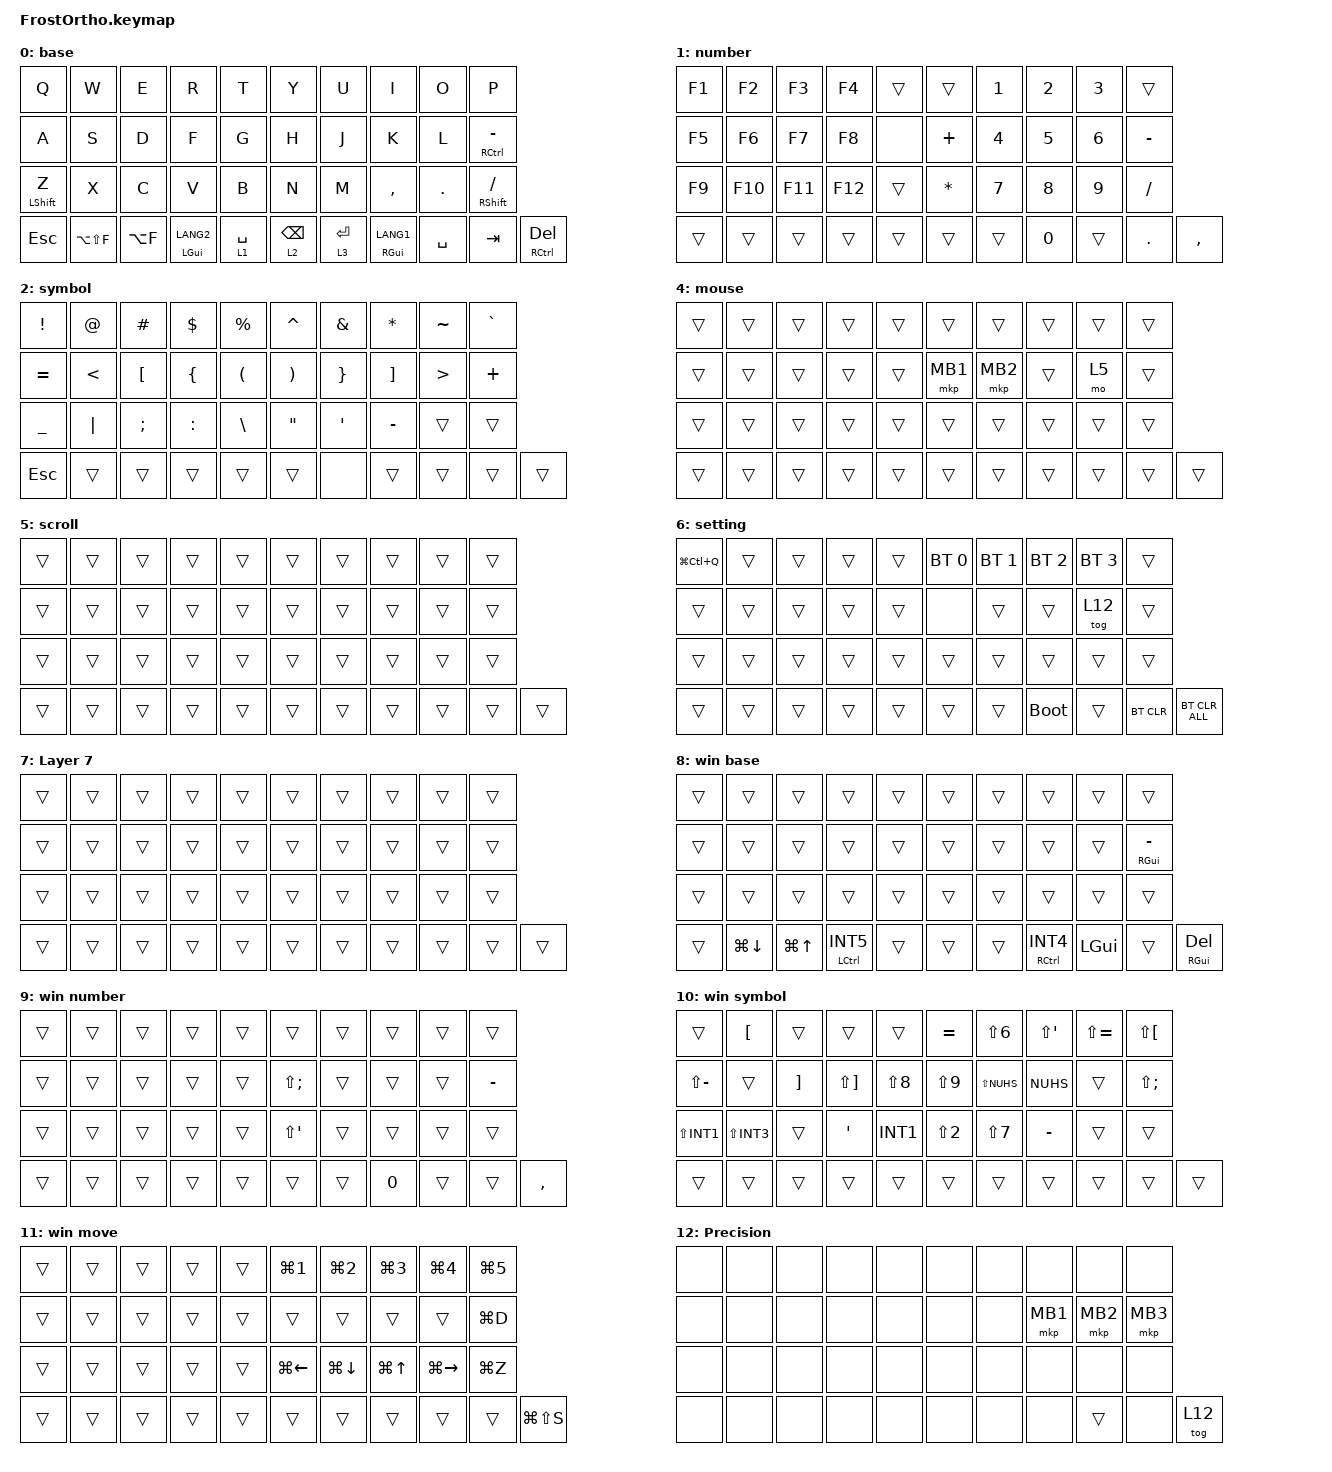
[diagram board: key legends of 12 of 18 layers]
#include <input/processors.dtsi>
#include <behaviors/runtime-sensor-rotate.dtsi>
#include <behaviors.dtsi>
#include <dt-bindings/zmk/bt.h>
#include <dt-bindings/zmk/keys.h>
#include <dt-bindings/zmk/pointing.h>
#include <behaviors/runtime-sensor-rotate.dtsi>

#define MOUSE 4
#define WIN 8 // Kconfig の FROSTORTHO_WIN_LAYER と揃える

&mt {
    flavor = "balanced";
    quick-tap-ms = <0>;
};

// AML クリックしたときにタイムアウトを延長
&mkp_input_listener { input-processors = <&zip_temp_layer MOUSE 5000>; };

/ {
    combos {
        compatible = "zmk,combos";

        combo_rctrl {
            timeout-ms = <50>;
            key-positions = <17 18>;
            layers = <0 1 2 3 4 5 6 7 12 13>; // Macのみ
            bindings = <&kp RCTRL>;
        };

        combo_ralt {
            timeout-ms = <50>;
            key-positions = <16 17>;
            bindings = <&kp RALT>;
        };

        combo_lctrl {
            timeout-ms = <50>;
            key-positions = <11 12>;
            layers = <0 1 2 3 4 5 6 7 12 13>; // Macのみ
            bindings = <&kp LCTRL>;
        };

        combo_lalt {
            timeout-ms = <50>;
            key-positions = <12 13>;
            bindings = <&kp LALT>;
        };

        // Windows: CmdをCtrlに入れ替えたぶん、Mac側のCtrlコンボはWinキーにする
        combo_win_rgui {
            timeout-ms = <50>;
            key-positions = <17 18>;
            layers = <8 9 10 11 14 15 16 17>;
            bindings = <&kp RGUI>;
        };

        combo_win_lgui {
            timeout-ms = <50>;
            key-positions = <11 12>;
            layers = <8 9 10 11 14 15 16 17>;
            bindings = <&kp LGUI>;
        };

        combo_tab {
            timeout-ms = <50>;
            key-positions = <1 2>;
            bindings = <&kp TAB>;
        };

        combo_space {
            timeout-ms = <50>;
            key-positions = <27 28>;
            bindings = <&kp SPACE>;
        };

        combo_gesture {
            timeout-ms = <50>;
            key-positions = <7 8>;
            bindings = <&mo 13>;
        };

        // Space+BS同時押しで設定レイヤー
        combo_setting {
            timeout-ms = <50>;
            require-prior-idle-ms = <150>; // 打鍵中の誤爆防止
            key-positions = <34 35>;
            bindings = <&mo 6>;
        };

        combo_bootloader {
            timeout-ms = <50>;
            key-positions = <8 24 4>;
            bindings = <&bootloader>;
        };
    };

    // WIN(レイヤー8)有効中は、各レイヤーのWindows差分を自動で重ねる
    conditional_layers {
        compatible = "zmk,conditional-layers";

        win_number {
            if-layers = <1 WIN>;
            then-layer = <9>;
        };
        win_symbol {
            if-layers = <2 WIN>;
            then-layer = <10>;
        };
        win_move {
            if-layers = <3 WIN>;
            then-layer = <11>;
        };
        win_setting {
            if-layers = <6 WIN>;
            then-layer = <14>;
        };
        win_gesture {
            if-layers = <13 WIN>;
            then-layer = <15>;
        };
        win_mouse {
            if-layers = <MOUSE WIN>;
            then-layer = <16>;
        };
        win_scroll {
            if-layers = <5 WIN>;
            then-layer = <17>;
        };
    };

    macros {
        to_layer_0: to_layer_0 {
            compatible = "zmk,behavior-macro-one-param";
            #binding-cells = <1>;
            bindings = <&to 0 &macro_param_1to1 &kp MACRO_PLACEHOLDER>;
            label = "TO_LAYER_0";
        };

        screenshot: screenshot {
            compatible = "zmk,behavior-macro";
            #binding-cells = <0>;
            bindings =
                <&to 7>,
                <&macro_press>,
                <&kp LEFT_WIN &kp LEFT_SHIFT &kp S>,
                <&macro_release>,
                <&kp LEFT_WIN &kp LEFT_SHIFT &kp S>;

            label = "SCREENSHOT";
        };
    };

    behaviors {
        // タップ直後に再度押し続けるとタップキーを連続入力するレイヤータップ
        lt_qt: lt_quick_tap {
            compatible = "zmk,behavior-hold-tap";
            #binding-cells = <2>;
            flavor = "tap-preferred";
            tapping-term-ms = <200>;
            quick-tap-ms = <200>;
            bindings = <&mo>, <&kp>;
        };
        lt_to_layer_0: lt_to_layer_0 {
            compatible = "zmk,behavior-hold-tap";
            label = "LAYER_TAP_TO_0";
            bindings = <&mo>, <&to_layer_0>;

            #binding-cells = <2>;
            tapping-term-ms = <300>;
        };
        // Kyemap Editor用
        scroll_up_down: behavior_sensor_rotate_mouse_wheel_up_down {
            compatible = "zmk,behavior-sensor-rotate";
            #sensor-binding-cells = <0>;
            tap-ms = <20>;
            bindings = <&msc SCRL_UP>, <&msc SCRL_DOWN>;
        };
        vol_up_down: vol_up_down {
            compatible = "zmk,behavior-sensor-rotate";
            #sensor-binding-cells = <0>;
            tap-ms = <5>;
            bindings = <&kp C_VOL_DN>, <&kp C_VOL_UP>;
        };
        // DYA Studio用
        rsr_vol: rsr_vol {
            compatible = "zmk,behavior-runtime-sensor-rotate";
            #sensor-binding-cells = <0>;
            tap-ms = <5>;
            cw-binding = <&kp C_VOL_DN>;
            ccw-binding = <&kp C_VOL_UP>;
        };
        rsr_scroll: rsr_scroll {
            compatible = "zmk,behavior-runtime-sensor-rotate";
            #sensor-binding-cells = <0>;
            tap-ms = <20>;
            cw-binding = <&msc SCRL_DOWN>;
            ccw-binding = <&msc SCRL_UP>;
        };
        rsr_hscroll: rsr_hscroll {
            compatible = "zmk,behavior-runtime-sensor-rotate";
            #sensor-binding-cells = <0>;
            tap-ms = <20>;
            cw-binding = <&msc SCRL_RIGHT>;
            ccw-binding = <&msc SCRL_LEFT>;
        };
        // Windows用: Macのナチュラルスクロールと同じ向きになるよう逆転
        rsr_scroll_win: rsr_scroll_win {
            compatible = "zmk,behavior-runtime-sensor-rotate";
            #sensor-binding-cells = <0>;
            tap-ms = <20>;
            cw-binding = <&msc SCRL_UP>;
            ccw-binding = <&msc SCRL_DOWN>;
        };
        rsr_hscroll_win: rsr_hscroll_win {
            compatible = "zmk,behavior-runtime-sensor-rotate";
            #sensor-binding-cells = <0>;
            tap-ms = <20>;
            cw-binding = <&msc SCRL_LEFT>;
            ccw-binding = <&msc SCRL_RIGHT>;
        };
    };

    keymap {
        compatible = "zmk,keymap";

        layer_0_base {
            display-name = "base";
            bindings = <
&kp Q            &kp W            &kp E            &kp R            &kp T                &kp Y            &kp U            &kp I            &kp O            &kp P
&kp A            &kp S            &kp D            &kp F            &kp G                &kp H            &kp J            &kp K            &kp L            &mt RCTRL MINUS
&mt LSHIFT Z     &kp X            &kp C            &kp V            &kp B                &kp N            &kp M            &kp COMMA        &kp DOT          &mt RSHIFT FSLH
&kp ESC          &kp LA(LS(F))    &kp LA(F)        &mt LGUI LANG2   &lt 1 SPACE      &lt_qt 2 BSPC        &lt 3 ENTER      &mt RGUI LANG1   &kp SPACE        &kp TAB          &mt RCTRL DEL
            >;

            sensor-bindings = <&rsr_scroll &rsr_trans>;
        };

        layer_1_number {
            display-name = "number";
            bindings = <
&kp F1     &kp F2     &kp F3     &kp F4     &trans         &trans     &kp N1     &kp N2     &kp N3     &trans
&kp F5     &kp F6     &kp F7     &kp F8     &none          &kp PLUS   &kp N4     &kp N5     &kp N6     &kp MINUS
&kp F9     &kp F10    &kp F11    &kp F12    &trans         &kp STAR   &kp N7     &kp N8     &kp N9     &kp FSLH
&trans     &trans     &trans     &trans     &trans     &trans         &trans     &kp N0     &trans     &kp DOT    &kp COMMA
            >;

            sensor-bindings = <&rsr_scroll &rsr_trans>;
        };

        layer_2_symbol {
            display-name = "symbol";
            bindings = <
&kp EXCL   &kp AT     &kp HASH   &kp DLLR   &kp PRCNT      &kp CARET  &kp AMPS   &kp STAR   &kp TILDE  &kp GRAVE
&kp EQUAL  &kp LT     &kp LBKT   &kp LBRC   &kp LPAR       &kp RPAR   &kp RBRC   &kp RBKT   &kp GT     &kp PLUS
&kp UNDER  &kp PIPE   &kp SEMI   &kp COLON  &kp BSLH       &kp DQT    &kp SQT    &kp MINUS  &trans     &trans
&kp ESC    &trans     &trans     &trans     &trans     &trans         &none      &trans     &trans     &trans     &trans
            >;

            sensor-bindings = <&rsr_scroll &rsr_trans>;
        };

        layer_3_move {
            display-name = "move";
            bindings = <
&kp HOME           &kp LS(LC(TAB))    &kp PG_UP          &kp LC(TAB)        &kp END                &kp LA(N1)         &kp LA(N2)         &kp LA(N3)         &kp LA(N4)         &kp LA(N5)
&kp C_MUTE         &kp C_VOL_DN       &kp C_VOL_UP       &kp C_BRI_DN       &kp C_BRI_UP           &kp LEFT           &kp DOWN           &kp UP             &kp RIGHT          &kp LA(N0)
&kp LSHIFT         &trans             &kp PG_DN          &trans             &trans                 &kp LA(LS(LC(H)))  &kp LA(LS(LC(J)))  &kp LA(LS(LC(K)))  &kp LA(LS(LC(L)))  &kp LA(LS(B))
&trans             &trans             &trans             &trans             &trans             &trans                 &trans             &trans             &trans             &trans             &kp LG(LS(N4))
            >;

            sensor-bindings = <&rsr_hscroll &rsr_trans>;
        };

        layer_4_mouse {
            display-name = "mouse";
            bindings = <
&trans    &trans    &trans    &trans    &trans        &trans    &trans    &trans    &trans    &trans
&trans    &trans    &trans    &trans    &trans        &mkp MB1  &mkp MB2  &trans    &mo 5     &trans
&trans    &trans    &trans    &trans    &trans        &trans    &trans    &trans    &trans    &trans
&trans    &trans    &trans    &trans    &trans    &trans        &trans    &trans    &trans    &trans    &trans
            >;

            sensor-bindings = <&rsr_scroll &rsr_trans>;
        };

        layer_5_scroll {
            display-name = "scroll";
            bindings = <
&trans  &trans  &trans  &trans  &trans      &trans  &trans  &trans  &trans  &trans
&trans  &trans  &trans  &trans  &trans      &trans  &trans  &trans  &trans  &trans
&trans  &trans  &trans  &trans  &trans      &trans  &trans  &trans  &trans  &trans
&trans  &trans  &trans  &trans  &trans  &trans      &trans  &trans  &trans  &trans  &trans
            >;

            sensor-bindings = <&rsr_scroll &rsr_trans>;
        };

        layer_6_setting {
            display-name = "setting";
            bindings = <
&kp LG(LC(Q))   &trans          &trans          &trans          &trans              &bt BT_SEL 0    &bt BT_SEL 1    &bt BT_SEL 2    &bt BT_SEL 3    &trans
&trans          &trans          &trans          &trans          &trans              &none           &trans          &trans          &tog 12         &trans
&trans          &trans          &trans          &trans          &trans              &trans          &trans          &trans          &trans          &trans
&trans          &trans          &trans          &trans          &trans          &trans              &trans          &bootloader     &trans          &bt BT_CLR      &bt BT_CLR_ALL
            >;

            sensor-bindings = <&rsr_scroll &rsr_trans>;
        };

        layer_7_layer_7 {
            display-name = "Layer 7";
            bindings = <
&trans  &trans  &trans  &trans  &trans      &trans  &trans  &trans  &trans  &trans
&trans  &trans  &trans  &trans  &trans      &trans  &trans  &trans  &trans  &trans
&trans  &trans  &trans  &trans  &trans      &trans  &trans  &trans  &trans  &trans
&trans  &trans  &trans  &trans  &trans  &trans      &trans  &trans  &trans  &trans  &trans
            >;

            sensor-bindings = <&rsr_scroll &rsr_trans>;
        };

        layer_8_win_base {
            display-name = "win base";
            bindings = <
&trans             &trans             &trans             &trans             &trans             &trans             &trans             &trans             &trans             &trans
&trans             &trans             &trans             &trans             &trans             &trans             &trans             &trans             &trans             &mt RGUI MINUS
&trans             &trans             &trans             &trans             &trans             &trans             &trans             &trans             &trans             &trans
&trans             &kp LG(DOWN)       &kp LG(UP)         &mt LCTRL INT5     &trans             &trans             &trans             &mt RCTRL INT4     &kp LGUI           &trans             &mt RGUI DEL
            >;

            sensor-bindings = <&rsr_scroll_win &rsr_trans>;
        };

        layer_9_win_number {
            display-name = "win number";
            bindings = <
&trans             &trans             &trans             &trans             &trans             &trans             &trans             &trans             &trans             &trans
&trans             &trans             &trans             &trans             &trans             &kp LS(SEMI)       &trans             &trans             &trans             &kp MINUS
&trans             &trans             &trans             &trans             &trans             &kp LS(SQT)        &trans             &trans             &trans             &trans
&trans             &trans             &trans             &trans             &trans             &trans             &trans             &kp N0             &trans             &trans             &kp COMMA
            >;

            sensor-bindings = <&rsr_scroll_win &rsr_trans>;
        };

        layer_10_win_symbol {
            display-name = "win symbol";
            bindings = <
&trans             &kp LBKT           &trans             &trans             &trans             &kp EQUAL          &kp LS(N6)         &kp LS(SQT)        &kp LS(EQUAL)      &kp LS(LBKT)
&kp LS(MINUS)      &trans             &kp RBKT           &kp LS(RBKT)       &kp LS(N8)         &kp LS(N9)         &kp LS(NUHS)       &kp NUHS           &trans             &kp LS(SEMI)
&kp LS(INT1)       &kp LS(INT3)       &trans             &kp SQT            &kp INT1           &kp LS(N2)         &kp LS(N7)         &kp MINUS          &trans             &trans
&trans             &trans             &trans             &trans             &trans             &trans             &trans             &trans             &trans             &trans             &trans
            >;

            sensor-bindings = <&rsr_scroll_win &rsr_trans>;
        };

        layer_11_win_move {
            display-name = "win move";
            bindings = <
&trans             &trans             &trans             &trans             &trans             &kp LG(N1)         &kp LG(N2)         &kp LG(N3)         &kp LG(N4)         &kp LG(N5)
&trans             &trans             &trans             &trans             &trans             &trans             &trans             &trans             &trans             &kp LG(D)
&trans             &trans             &trans             &trans             &trans             &kp LG(LEFT)       &kp LG(DOWN)       &kp LG(UP)         &kp LG(RIGHT)      &kp LG(Z)
&trans             &trans             &trans             &trans             &trans             &trans             &trans             &trans             &trans             &trans             &kp LG(LS(S))
            >;

            sensor-bindings = <&rsr_hscroll_win &rsr_trans>;
        };

        layer_12_precision {
            display-name = "Precision";
            bindings = <
&none     &none     &none     &none     &none         &none     &none     &none     &none     &none
&none     &none     &none     &none     &none         &none     &none     &mkp MB1  &mkp MB2  &mkp MB3
&none     &none     &none     &none     &none         &none     &none     &none     &none     &none
&none     &none     &none     &none     &none     &none         &none     &none     &trans    &none     &tog 12
            >;

            sensor-bindings = <&rsr_scroll &rsr_trans>;
        };

        layer_13_gesture {
            display-name = "Gesture";
            bindings = <
&none          &none          &none          &none          &none              &none          &none          &kp LC(DOWN)   &none          &none
&none          &none          &none          &none          &none              &none          &kp LC(RIGHT)  &none          &kp LC(LEFT)   &none
&none          &none          &none          &none          &none              &none          &none          &kp LC(UP)     &none          &none
&none          &none          &none          &none          &none          &none              &none          &none          &trans         &none          &none
            >;

            sensor-bindings = <&rsr_scroll &rsr_trans>;
        };

        layer_14_win_setting {
            display-name = "win setting";
            bindings = <
&kp LG(L)          &trans             &trans             &trans             &trans             &trans             &trans             &trans             &trans             &trans
&trans             &trans             &trans             &trans             &trans             &trans             &trans             &trans             &trans             &trans
&trans             &trans             &trans             &trans             &trans             &trans             &trans             &trans             &trans             &trans
&trans             &trans             &trans             &trans             &trans             &trans             &trans             &bootloader        &trans             &trans             &bt BT_CLR_ALL
            >;

            sensor-bindings = <&rsr_scroll_win &rsr_trans>;
        };

        layer_15_win_gesture {
            display-name = "win gesture";
            bindings = <
&trans             &trans             &trans             &trans             &trans             &trans             &trans             &kp LA(LC(TAB))    &trans             &trans
&trans             &trans             &trans             &trans             &trans             &trans             &kp LG(LC(RIGHT))  &trans             &kp LG(LC(LEFT))   &trans
&trans             &trans             &trans             &trans             &trans             &trans             &trans             &kp LG(TAB)        &trans             &trans
&trans             &trans             &trans             &trans             &trans             &trans             &trans             &trans             &trans             &trans             &trans
            >;

            sensor-bindings = <&rsr_scroll_win &rsr_trans>;
        };

        layer_16_win_mouse {
            display-name = "win mouse";
            bindings = <
&trans             &trans             &trans             &trans             &trans             &trans             &trans             &trans             &trans             &trans
&trans             &trans             &trans             &trans             &trans             &trans             &trans             &trans             &trans             &trans
&trans             &trans             &trans             &trans             &trans             &trans             &trans             &trans             &trans             &trans
&trans             &trans             &trans             &trans             &trans             &trans             &trans             &trans             &trans             &trans             &trans
            >;

            sensor-bindings = <&rsr_scroll_win &rsr_trans>;
        };

        layer_17_win_scroll {
            display-name = "win scroll";
            bindings = <
&trans             &trans             &trans             &trans             &trans             &trans             &trans             &trans             &trans             &trans
&trans             &trans             &trans             &trans             &trans             &trans             &trans             &trans             &trans             &trans
&trans             &trans             &trans             &trans             &trans             &trans             &trans             &trans             &trans             &trans
&trans             &trans             &trans             &trans             &trans             &trans             &trans             &trans             &trans             &trans             &trans
            >;

            sensor-bindings = <&rsr_scroll_win &rsr_trans>;
        };
    };
};
